# BL808 register map
File version: 0.1
Registers are access not given, no defined reset value unless marked. A register's access mark holds for its fields unless they carry their own. Offsets are from the block's base; [hi:lo] are bit positions; {n}, {i} and the like mark numbered series.

## SDH (part 1 of 2)
Base 0x20060000
0x00 SDMA_System_Address_Argument_2 rw
  [31:0] SDMASystem — SDMA System Address / Argument 2 This register contains the physical system memory address used for DMA transfers or the second argument for the Auto CMD23. (1) SDMA System Address This register contains the system memory address for a SDMA transfer. When the Host Controller stops a SDMA transfer, this register shall point to the system address of the next contiguous data position. It can be accessed only if no transaction is executing (i.e., after a transaction has stopped). Read operations during transfers may return an invalid value. (2) Argument 2 This register is used with the Auto CMD23 to set a 32-bit block count value to the argument of the CMD23 while executing Auto CMD23.
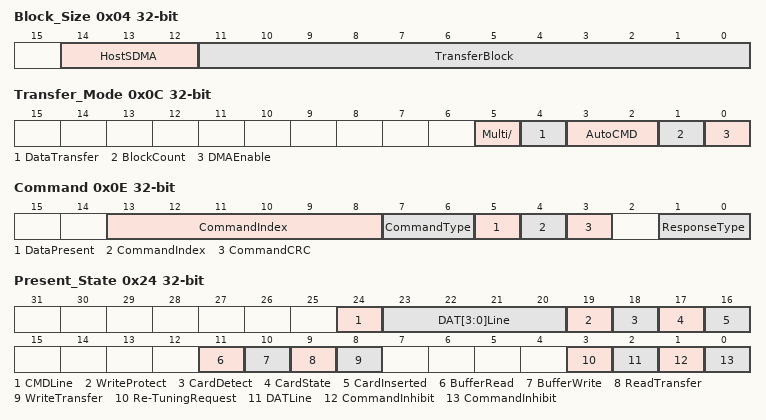
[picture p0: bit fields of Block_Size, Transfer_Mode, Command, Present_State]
0x04 Block_Size
  [14:12] HostSDMA rw — Host SDMA Buffer Boundary The large contiguous memory space may not be available in the virtual memory system. To perform long SDMA transfer, SDMA System Address register shall be updated at every system memory boundary during SDMA transfer. These bits specify the size of contiguous buffer in the system memory. The SDMA transfer shall wait at the every boundary specified by these fields and the Host Controller generates the DMA Interrupt to request the Host Driver to update the SDMA System Address register. At the end of transfer, the Host Controller may issue or may not issue DMA Interrupt. In particular, DMA Interrupt shall not be issued after Transfer Complete Interrupt is issued. In case of this register is set to 0 (buffer size = 4K bytes), lower 12-bit of byte address points data in the contiguous buffer and the upper 20-bit points the location of the buffer in the system memory. The SDMA transfer stops when the Host Controller detects carry out of the address from bit 11 to 12. These bits shall be supported when the SDMA Support in the Capabilities register is set to 1 and this function is active when the DMA Enable in the Transfer Mode register is set to 1. ADMA does not use this register.
  [11:0] TransferBlock rw — Transfer Block Size This register specifies the block size of data transfers for CMD17, CMD18, CMD24, CMD25, and CMD53. Values ranging from 1 up to the maximum buffer size can be set. In case of memory, it shall be set up to 512 bytes (Refer to Implementation Note in Section 1.7.2). It can be accessed only if no transaction is executing (i.e., after a transaction has stopped). Read operations during transfers may return an invalid value, and write operations shall be ignored.
0x06 Block_Count
  [15:0] BlocksCount rw — Blocks Count For Current Transfer This register is enabled when Block Count Enable in the Transfer Mode register is set to 1 and is valid only for multiple block transfers. The Host Driver shall set this register to a value between 1 and the maximum block count. The Host Controller decrements the block count after each block transfer and stops when the count reaches zero. Setting the block count to 0 results in no data blocks is transferred. This register should be accessed only when no transaction is executing (i.e., after transactions are stopped). During data transfer, read operations on this register may return an invalid value and write operations are ignored. When a suspend command is completed, the number of blocks yet to be transferred can be determined by reading this register. Before issuing a resume command, the Host Driver shall restore the previously saved block count.
0x08 Argument_1 rw
  [31:0] CommandArgument — Command Argument 1 The SD command argument is specified as bit39-8 of Command-Format in the Physical Layer Specification.
0x0C Transfer_Mode
  [5] Multi/ rw — Multi / Single Block Select This bit is set when issuing multiple-block transfer commands using DAT line. For any other commands, this bit shall be set to 0. If this bit is 0, it is not necessary to set the Block Count register. (Refer to Table 2-8)
  [4] DataTransfer rw — Data Transfer Direction Select This bit defines the direction of DAT line data transfers. The bit is set to 1 by the Host Driver to transfer data from the SD card to the SD Host Controller and it is set to 0 for all other commands.
  [3:2] AutoCMD rw — Auto CMD Enable This field determines use of auto command functions. (1) Auto CMD12 Enable (2) Auto CMD23 Enable
  [1] BlockCount rw — This bit is used to enable the Block Count register, which is only relevant for multiple block transfers. When this bit is 0, the Block Count register is disabled, which is useful in executing an infinite transfer. If ADMA2 data transfer is more than 65535 blocks, this bit shall be set to 0. In this case, data transfer length is designated by Descriptor Table.
  [0] DMAEnable rw — This bit enables DMA functionality as described in section 1.4. DMA can be enabled only if it is supported as indicated in the Capabilities register. One of the DMA modes can be selected by DMA Select in the Host Control 1 register. If DMA is not supported, this bit is meaningless and shall always read 0. If this bit is set to 1, a DMA operation shall begin when the Host Driver writes to the upper byte of Command register (00Fh).
0x0E Command
  [13:8] CommandIndex rw — These bits shall be set to the command number (CMD0-63, ACMD0-63) that is specified in bits 45-40 of the Command-Format in the Physical Layer Specification and SDIO Card Specification.
  [7:6] CommandType rw — There are three types of special commands: Suspend, Resume and Abort. These bits shall be set to 00b for all other commands. (1) Suspend Command (2) Resume Command (3) Abort Command
  [5] DataPresent rw — This bit is set to 1 to indicate that data is present and shall be transferred using the DAT line. It is set to 0 for the following: (1) Commands using only CMD line (ex. CMD52). (2) Commands with no data transfer but using busy signal on DAT[0] line (R1b or R5b ex. CMD38) (3) Resume command
  [4] CommandIndex rw — If this bit is set to 1, the Host Controller shall check the Index field in the response to see if it has the same value as the command index. If it is not, it is reported as a Command Index Error. If this bit is set to 0, the Index field is not checked.
  [3] CommandCRC rw — If this bit is set to 1, the Host Controller shall check the CRC field in the response. If an error is detected, it is reported as a Command CRC Error. If this bit is set to 0, the CRC field is not checked. The position of CRC field is determined according to the length of the response. (Refer to definition in D01-00 and Table 2-10 below.)
  [1:0] ResponseType rw — 00: No Response 01: Response Length 136 10: Response Length 48 11: Response Length 48 check Busy after response
{0xC+4i} Response_{i} rw (i=1..4)
  [31:0] CommandResponse
0x20 Buffer_Data_Port rw
  [31:0] BufferData — Buffer Data The Host Controller buffer can be accessed through this 32-bit Data Port register.
0x24 Present_State
  [24] CMDLine ro — CMD Line Signal Level This status is used to check the CMD line level to recover from errors, and for debugging.
  [23:20] DAT[3:0]Line ro — DAT[3:0] Line Signal Level This status is used to check the DAT line level to recover from errors, and for debugging. This is especially useful in detecting the busy signal level from DAT[0].
  [19] WriteProtect ro — The Write Protect Switch is supported for memory and combo cards. This bit reflects the SDWP# pin.
  [18] CardDetect ro — This bit reflects the inverse value of the SDCD# pin. Debouncing is not performed on this bit. This bit may be valid when Card State Stable is set to 1, but it is not guaranteed because of propagation delay. Use of this bit is limited to testing since it must be debounced by software.
  [17] CardState ro — This bit is used for testing. If it is 0, the Card Detect Pin Level is not stable. If this bit is set to 1, it means the Card Detect Pin Level is stable. No Card state can be detected by this bit is set to 1 and Card Inserted is set to 0. The Software Reset For All in the Software Reset register shall not affect this bit.
  [16] CardInserted ro — This bit indicates whether a card has been inserted. The Host Controller shall debounce this signal so that the Host Driver will not need to wait for it to stabilize. Changing from 0 to 1 generates a Card Insertion interrupt in the Normal Interrupt Status register and changing from 1 to 0 generates a Card Removal interrupt in the Normal Interrupt Status register. The Software Reset For All in the Software Reset register shall not affect this bit. If a card is removed while its power is on and its clock is oscillating, the Host Controller shall clear SD Bus Power in the Power Control register and SD Clock Enable in the Clock Control register When this bit is changed from 1 to 0, the Host Controller shall immediately stop driving CMD and DAT[3:0] (tri-state). In addition, the Host Driver should clear the Host Controller by the Software Reset For All in Software Reset register. The card detect is active regardless of the SD Bus Power.
  [11] BufferRead ro — Buffer Read Enable This status is used for non-DMA read transfers. The Host Controller may implement multiple buffers to transfer data efficiently. This read only flag indicates that valid data exists in the host side buffer. If this bit is 1, readable data exists in the buffer. A change of this bit from 1 to 0 occurs when all the block data is read from the buffer. A change of this bit from 0 to 1 occurs when block data is ready in the buffer and generates the Buffer Read Ready interrupt.
  [10] BufferWrite ro — Buffer Write Enable This status is used for non-DMA write transfers. The Host Controller can implement multiple buffers to transfer data efficiently. This read only flag indicates if space is available for write data. If this bit is 1, data can be written to the buffer. A change of this bit from 1 to 0 occurs when all the block data is written to the buffer. A change of this bit from 0 to 1 occurs when top of block data can be written to the buffer and generates the Buffer Write Ready interrupt. The Host Controller should neither set Buffer Write Enable nor generate Buffer Write Ready Interrupt after the last block data is written to the Buffer Data Port Register.
  [9] ReadTransfer ro — Read Transfer Active This status is used for detecting completion of a read transfer. This bit is set to 1 for either of the following conditions: (1) After the end bit of the read command. (2) When read operation is restarted by writing a 1 to Continue Request in the Block Gap Control register. This bit is cleared to 0 for either of the following conditions:: (1) When the last data block as specified by block length is transferred to the System. (2) In case of ADMA2, end of read operation is designated by Descriptor Table. (3) When all valid data blocks in the Host Controller have been transferred to the System and no current block transfers are being sent as a result of the Stop At Block Gap Request being set to 1. A Transfer Complete interrupt is generated when this bit changes to 0.
  [8] WriteTransfer ro — Write Transfer Active This status indicates a write transfer is active. If this bit is 0, it means no valid write data exists in the Host Controller. Refer to Section 3.12.4 for more details on the sequence of events. This bit is set in either of the following cases: (1) After the end bit of the write command. (2) When write operation is restarted by writing a 1 to Continue Request in the Block Gap Control register. This bit is cleared in either of the following cases: (1) After getting the CRC status of the last data block as specified by the transfer count (Single and Multiple) In case of ADMA2, transfer count is designated by Descriptor Table. (2) After getting the CRC status of any block where data transmission is about to be stopped by a Stop At Block Gap Request. During a write transaction, a Block Gap Event interrupt is generated when this bit is changed to 0, as the result of the Stop At Block Gap Request being set. This status is useful for the Host Driver in determining non DAT line commands can be issued during write busy.
  [3] Re-TuningRequest ro — Re-Tuning Request Host Controller may request Host Driver to execute re-tuning sequence by setting this bit when the data window is shifted by temperature drift and a tuned sampling point does not have a good margin to receive correct data. This bit is cleared when a command is issued with setting Execute Tuning in the Host Control 2 register. Changing of this bit from 0 to 1 generates Re-Tuning Event. Refer to Normal Interrupt Status registers for more detail. This bit isn't set to 1 if Sampling Clock Select in the Host Control 2 register is set to 0 (using fixed sampling clock). Refer to Re-Tuning Modes in the Capabilities register for more detail.
  [2] DATLine ro — DAT Line Active This bit indicates whether one of the DAT line on SD Bus is in use.
  [1] CommandInhibit ro — This status bit is generated if either the DAT Line Active or the Read Transfer Active is set to 1. If this bit is 0, it indicates the Host Controller can issue the next SD Command. Commands with busy signal belong to Command Inhibit (DAT) (ex. R1b, R5b type). Changing from 1 to 0 generates a Transfer Complete interrupt in the Normal Interrupt Status register. Note: The SD Host Driver can save registers in the range of 000-00Dh for a suspend transaction after this bit has changed from 1 to 0.
  [0] CommandInhibit ro — If this bit is 0, it indicates the CMD line is not in use and the Host Controller can issue a SD Command using the CMD line. This bit is set immediately after the Command register (00Fh) is written. This bit is cleared when the command response is received. Auto CMD12 and Auto CMD23 consist of two responses. In this case, this bit is not cleared by the response of CMD12 or CMD23 but cleared by the response of a read/write command. Status issuing Auto CMD12 is not read from this bit. So if a command is issued during Auto CMD12 operation, Host Controller shall manage to issue two commands: CMD12 and a command set by Command register. Even if the Command Inhibit (DAT) is set to 1, commands using only the CMD line can be issued if this bit is 0. Changing from 1 to 0 generates a Command Complete Interrupt in the Normal Interrupt Status register. If the Host Controller cannot issue the command because of a command conflict error or because of Command Not Issued By Auto CMD12 Error, this bit shall remain 1 and the Command Complete is not set.
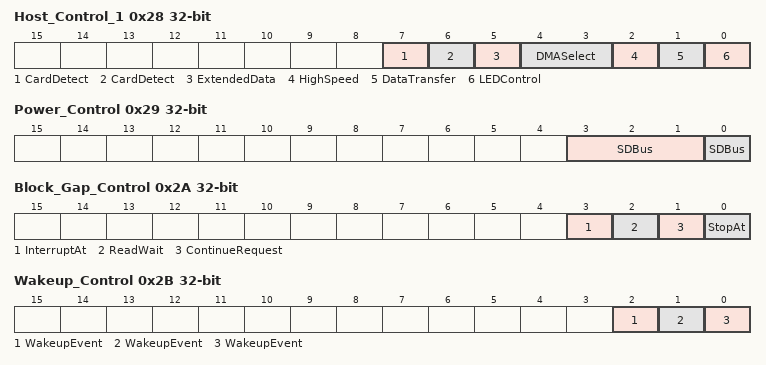
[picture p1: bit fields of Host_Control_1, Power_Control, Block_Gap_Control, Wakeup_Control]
0x28 Host_Control_1
  [7] CardDetect rw — This bit selects source for the card detection. 1: The Card Detect Test Level is selected (for test purpose) 0: SDCD# is selected (for normal use) When the source for the card detection is switched, the interrupt should be disabled during the switching period by clearing the Interrupt Status/Signal Enable register in order to mask unexpected interrupt being caused by the glitch. The Interrupt Status/Signal Enable should be disabled during over the period of debouncing.
  [6] CardDetect rw — This bit is enabled while the Card Detect Signal Selection is set to 1 and it indicates card inserted or not. 1 Card Inserted 0 No Card
  [5] ExtendedData rw — This bit controls 8-bit bus width mode for embedded device. Support of this function is indicated in 8-bit Support for Embedded Device in the Capabilities register. If a device supports 8-bit bus mode, this bit may be set to 1. If this bit is 0, bus width is controlled by Data Transfer Width in the Host Control 1 register. This bit is not effective when multiple devices are installed on a bus slot (Slot Type is set to 10b in the Capabilities register). In this case, each device bus width is controlled by Bus Width Preset field in the Shared Bus Control register. 1: 8-bit Bus Width 0 :Bus Width is Selected by Data Transfer Width
  [4:3] DMASelect rw — One of supported DMA modes can be selected. The host driver shall check support of DMA modes by referring the Capabilities register. Use of selected DMA is determined by DMA Enable of the Transfer Mode register. 00 SDMA is selected 01 Reserved (New assignment is not allowed) 10 32-bit Address ADMA2 is selected 11 Reserved (will be modified by Version 4.00)
  [2] HighSpeed rw — This bit is optional. Before setting this bit, the Host Driver shall check the High Speed Support in the Capabilities register. If this bit is set to 0 (default), the Host Controller outputs CMD line and DAT lines at the falling edge of the SD Clock (up to 25MHz). If this bit is set to 1, the Host Controller outputs CMD line and DAT lines at the rising edge of the SD Clock (up to 50MHz). If Preset Value Enable in the Host Control 2 register is set to 1, Host Driver needs to reset SD Clock Enable before changing this field to avoid generating clock glitches. After setting this field, the Host Driver sets SD Clock Enable again. 1 :High Speed mode 0 :Normal Speed mode
  [1] DataTransfer rw — This bit selects the data width of the Host Controller. The Host Driver shall set it to match the data width of the SD card. 1: 4-bit mode 0 :1-bit mode
  [0] LEDControl rw — This bit is used to caution the user not to remove the card while the SD card is being accessed. If the software is going to issue multiple SD commands, this bit can be set during all these transactions. It is not necessary to change for each transaction. 1 :LED on 0 :LED off
0x29 Power_Control
  [3:1] SDBus rw — SD Bus Voltage Select By setting these bits, the Host Driver selects the voltage level for the SD card. Before setting this register, the Host Driver shall check the Voltage Support bits in the Capabilities register. If an unsupported voltage is selected, the Host System shall not supply SD Bus voltage. 111b 3.3V (Typ.) 110b 3.0V (Typ.) 101b 1.8V (Typ.) 100b – 000b Reserved
  [0] SDBus rw — SD Bus Power Before setting this bit, the SD Host Driver shall set SD Bus Voltage Select. If the Host Controller detects the No Card state, this bit shall be cleared. If this bit is cleared, the Host Controller shall immediately stop driving CMD and DAT[3:0] (tri-state) and drive SDCLK to low level .
0x2A Block_Gap_Control
  [3] InterruptAt rw — Interrupt At Block Gap This bit is valid only in 4-bit mode of the SDIO card and selects a sample point in the interrupt cycle. Setting to 1 enables interrupt detection at the block gap for a multiple block transfer. Setting to 0 disables interrupt detection during a multiple block transfer. If the SD card cannot signal an interrupt during a multiple block transfer, this bit should be set to 0. When the Host Driver detects an SD card insertion, it shall set this bit according to the CCCR of the SDIO card.
  [2] ReadWait rw — Read Wait Control The read wait function is optional for SDIO cards. If the card supports read wait, set this bit to enable use of the read wait protocol to stop read data using the DAT[2] line. Otherwise, the Host Controller has to stop the SD Clock to hold read data, which restricts commands generation. When the Host Driver detects an SD card insertion, it shall set this bit according to the CCCR of the SDIO card. If the card does not support read wait, this bit shall never be set to 1 otherwise DAT line conflict may occur. If this bit is set to 0, Suspend/Resume cannot be supported.
  [1] ContinueRequest rw — This bit is used to restart a transaction, which was stopped using the Stop At Block Gap Request. To cancel stop at the block gap, set Stop At Block Gap Request to 0 and set this bit 1 to restart the transfer. The Host Controller automatically clears this bit in either of the following cases: (1) In the case of a read transaction, the DAT Line Active changes from 0 to 1 as a read transaction restarts. (2) In the case of a write transaction, the Write Transfer Active changes from 0 to 1 as the write transaction restarts. Therefore, it is not necessary for Host Driver to set this bit to 0. If Stop At Block Gap Request is set to 1, any write to this bit is ignored.
  [0] StopAt rw — This bit is used to stop executing read and write transaction at the next block gap for non-DMA, SDMA and ADMA transfers. The Host Driver shall leave this bit set to 1 until the Transfer Complete is set to 1. Clearing both Stop At Block Gap Request and Continue Request shall not cause the transaction to restart. When Host Controller version is 1.00, the Host Driver can set this bit if the card supports Read Wait Control. When Host Controller version is 2.00 or later, the Host Driver can set this bit regardless of the card supports Read Wait Control. The Host Controller shall stop read transfer by using Read Wait or stopping SD clock. In case of write transfers in which the Host Driver writes data to the Buffer Data Port register, the Host Driver shall set this bit after all block data is written. If this bit is set to 1, the Host Driver shall not write data to Buffer Data Port register. This bit affects Read Transfer Active, Write Transfer Active, DAT Line Active and Command Inhibit (DAT) in the Present State register.
0x2B Wakeup_Control
  [2] WakeupEvent rw — Wakeup Event Enable On SD Card Removal This bit enables wakeup event via Card Removal assertion in the Normal Interrupt Status register. FN_WUS (Wake Up Support) in CIS does not affect this bit.
  [1] WakeupEvent rw — Wakeup Event Enable On SD Card Insertion This bit enables wakeup event via Card Insertion assertion in the Normal Interrupt Status register. FN_WUS (Wake Up Support) in CIS does not affect this bit.
  [0] WakeupEvent rw — Wakeup Event Enable On Card Interrupt This bit enables wakeup event via Card Interrupt assertion in the Normal Interrupt Status register. This bit can be set to 1 if FN_WUS (Wake Up Support) in CIS is set to 1.
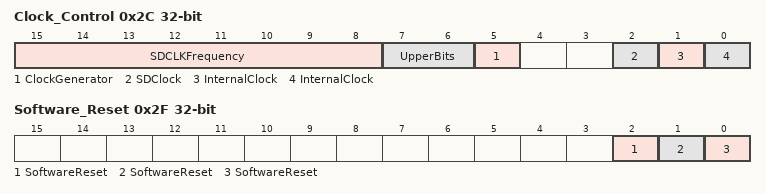
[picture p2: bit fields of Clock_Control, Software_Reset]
0x2C Clock_Control
  [15:8] SDCLKFrequency rw — SDCLK Frequency Select This register is used to select the frequency of SDCLK pin. The definition of this field is dependent on the Host Controller Version.
  [7:6] UpperBits rw — Upper Bits of SDCLK Frequency Select Host Controller Version 1.00 and 2.00 do not support these bits and they are treated as 00b fixed value (ROC). Host Controller Version 3.00 shall support these bits to expand SDCLK Frequency Select to 10-bit. Bit 07-06 is assigned to bit 09-08 of clock divider in SDCLK Frequency Select.
  [5] ClockGenerator rw — Clock Generator Select Host Controller Version 3.00 supports this bit. This bit is used to select the clock generator mode in SDCLK Frequency Select. If the Programmable Clock Mode is supported (non-zero value is set to Clock Multiplier in the Capabilities register), this bit attribute is RW, and if not supported, this bit attribute is RO and zero is read. This bit depends on the setting of Preset Value Enable in the Host Control 2 register. If the Preset Value Enable = 0, this bit is set by Host Driver. If the Preset Value Enable = 1, this bit is automatically set to a value specified in one of Preset Value registers. 1 Programmable Clock Mode 0 Divided Clock Mode
  [2] SDClock rw — SD Clock Enable The Host Controller shall stop SDCLK when writing this bit to 0. SDCLK Frequency Select can be changed when this bit is 0. Then, the Host Controller shall maintain the same clock frequency until SDCLK is stopped (Stop at SDCLK=0). If the Card Inserted in the Present State register is cleared, this bit shall be cleared.
  [1] InternalClock ro — Internal Clock Stable This bit is set to 1 when SD Clock is stable after writing to Internal Clock Enable in this register to 1. The SD Host Driver shall wait to set SD Clock Enable until this bit is set to 1. Note: This is useful when using PLL for a clock oscillator that requires setup time.
  [0] InternalClock rw — Internal Clock Enable This bit is set to 0 when the Host Driver is not using the Host Controller or the Host Controller awaits a wakeup interrupt. The Host Controller should stop its internal clock to go very low power state. Still, registers shall be able to be read and written. Clock starts to oscillate when this bit is set to 1. When clock oscillation is stable, the Host Controller shall set Internal Clock Stable in this register to 1. This bit shall not affect card detection.
0x2E Timeout_Control
  [3:0] DataTimeout rw — Data Timeout Counter Value This value determines the interval by which DAT line timeouts are detected. For more information about timeout generation, refer to the Data Timeout Error in the Error Interrupt Status register. Timeout clock frequency will be generated by dividing the base clock TMCLK value by this value. When setting this register, prevent inadvertent timeout events by clearing the Data Timeout Error Status Enable (in the Error Interrupt Status Enable register)
0x2F Software_Reset
  [2] SoftwareReset rw — Software Reset For DAT Line Only part of data circuit is reset. DMA circuit is also reset.
  [1] SoftwareReset rw — Software Reset For CMD Line Only part of command circuit is reset. The following registers and bits are cleared by this bit: Present State register Command Inhibit (CMD) Normal Interrupt Status register Command Complete
  [0] SoftwareReset rw — Software Reset For All This reset affects the entire Host Controller except for the card detection circuit. Register bits of type ROC, RW, RW1C, RWAC are cleared to 0. During its initialization, the Host Driver shall set this bit to 1 to reset the Host Controller. The Host Controller shall reset this bit to 0 when Capabilities registers are valid and the Host Driver can read them. Additional use of Software Reset For All may not affect the value of the Capabilities registers. If this bit is set to 1, the host driver should issue reset command and reinitialize the SD card.
